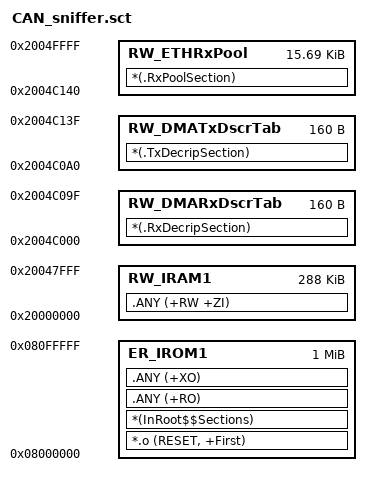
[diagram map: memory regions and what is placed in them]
; CanSniff STM32F746NGHx memory layout.
; 0x20048000..0x2004BFFF is the dedicated LwIP heap.
; Ethernet descriptors are fixed immediately above it.

LR_IROM1 0x08000000 0x00100000  {
  ER_IROM1 0x08000000 0x00100000  {
    *.o (RESET, +First)
    *(InRoot$$Sections)
    .ANY (+RO)
    .ANY (+XO)
  }
  RW_IRAM1 0x20000000 0x00048000  {
    .ANY (+RW +ZI)
  }
  RW_DMARxDscrTab 0x2004C000 0x000000A0  {
    *(.RxDecripSection)
  }
  RW_DMATxDscrTab 0x2004C0A0 0x000000A0  {
    *(.TxDecripSection)
  }
  RW_ETHRxPool 0x2004C140 0x00003EC0  {
    *(.RxPoolSection)
  }
}
